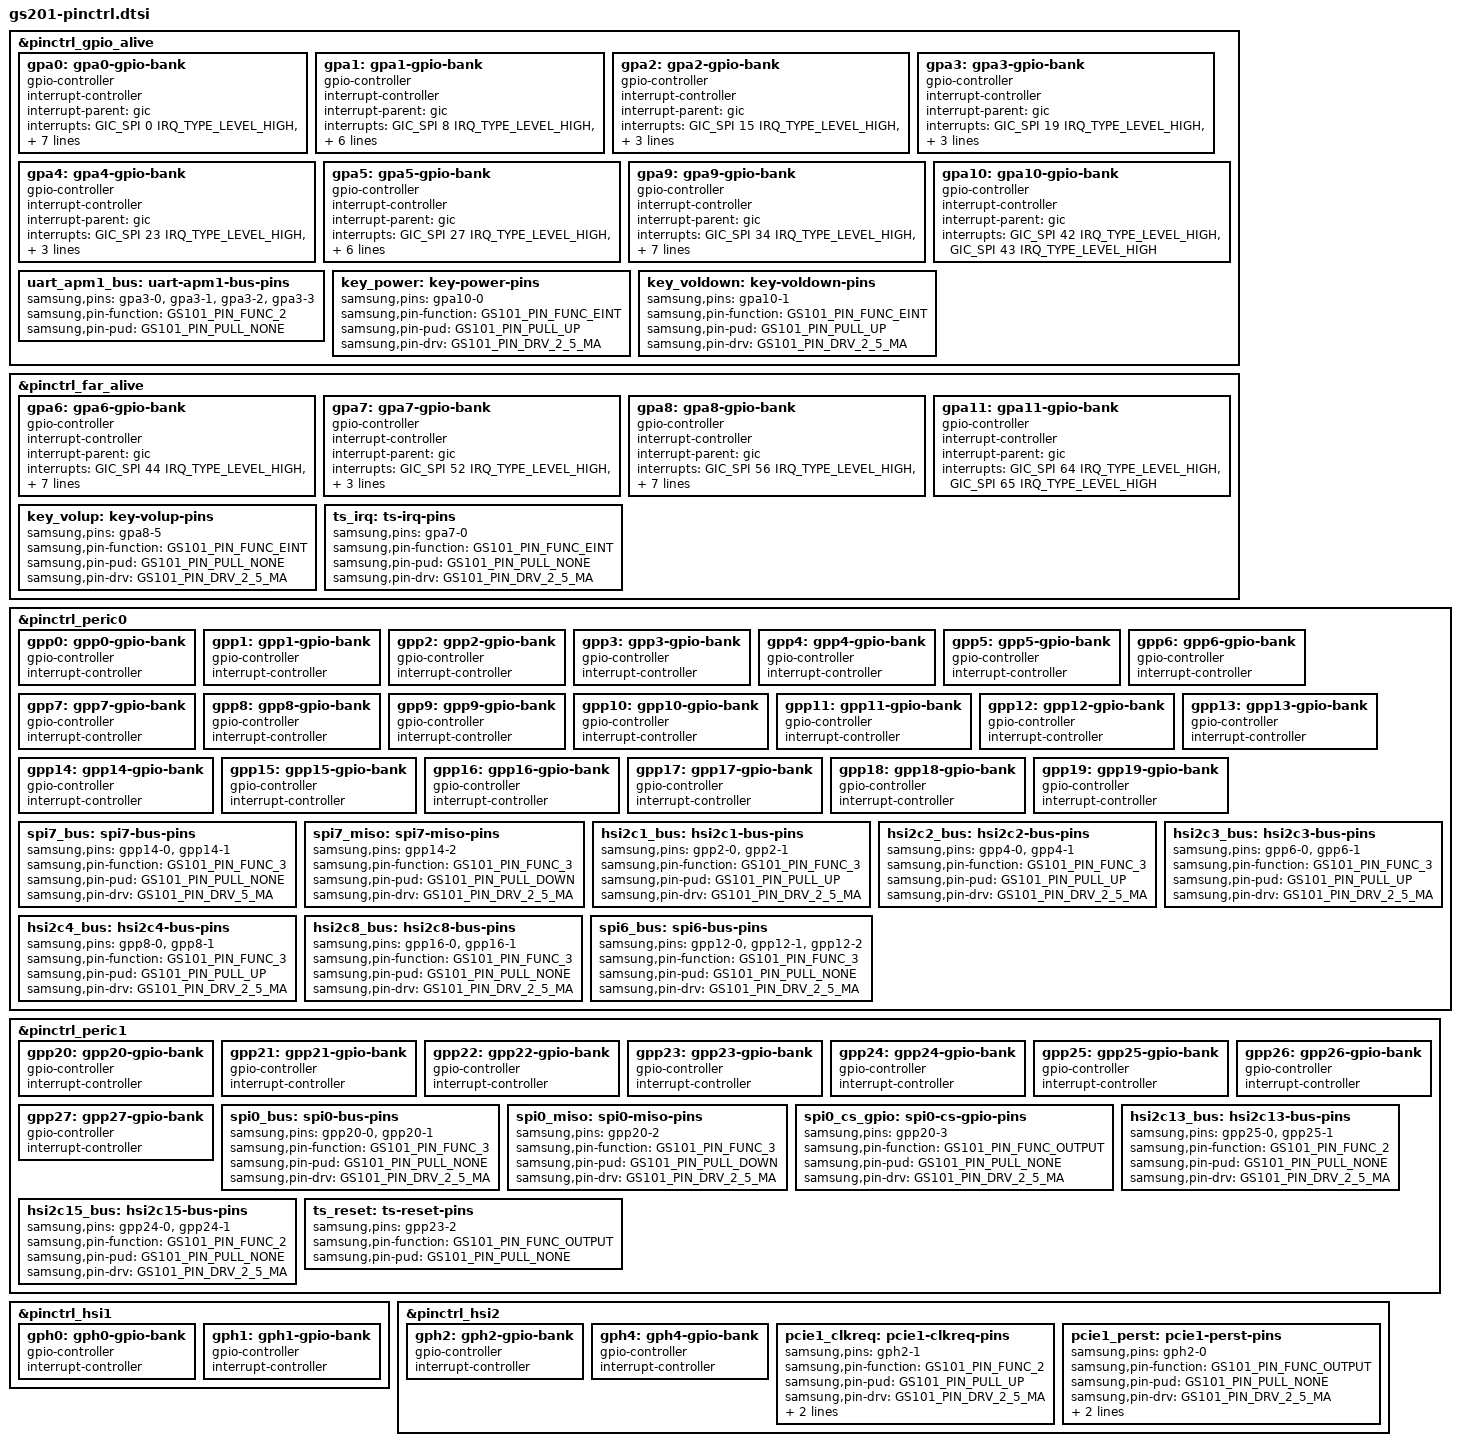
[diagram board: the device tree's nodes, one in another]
// SPDX-License-Identifier: GPL-2.0-only
/*
 * Google GS201 (Tensor G2) SoC pin-mux and pin-config device tree source
 *
 * Bank layout and wake-up interrupt numbers from Google's GPL gs201 device
 * tree. Note that the ALIVE wake-up interrupts skip EINT19, so from EINT20
 * on the GIC number is the EINT number minus one.
 */

#include "gs101-pinctrl.h"

&pinctrl_gpio_alive {
	gpa0: gpa0-gpio-bank {
		gpio-controller;
		#gpio-cells = <2>;
		interrupt-controller;
		#interrupt-cells = <2>;
		interrupt-parent = <&gic>;
		interrupts = <GIC_SPI 0 IRQ_TYPE_LEVEL_HIGH>,
			     <GIC_SPI 1 IRQ_TYPE_LEVEL_HIGH>,
			     <GIC_SPI 2 IRQ_TYPE_LEVEL_HIGH>,
			     <GIC_SPI 3 IRQ_TYPE_LEVEL_HIGH>,
			     <GIC_SPI 4 IRQ_TYPE_LEVEL_HIGH>,
			     <GIC_SPI 5 IRQ_TYPE_LEVEL_HIGH>,
			     <GIC_SPI 6 IRQ_TYPE_LEVEL_HIGH>,
			     <GIC_SPI 7 IRQ_TYPE_LEVEL_HIGH>;
	};

	gpa1: gpa1-gpio-bank {
		gpio-controller;
		#gpio-cells = <2>;
		interrupt-controller;
		#interrupt-cells = <2>;
		interrupt-parent = <&gic>;
		interrupts = <GIC_SPI 8 IRQ_TYPE_LEVEL_HIGH>,
			     <GIC_SPI 9 IRQ_TYPE_LEVEL_HIGH>,
			     <GIC_SPI 10 IRQ_TYPE_LEVEL_HIGH>,
			     <GIC_SPI 11 IRQ_TYPE_LEVEL_HIGH>,
			     <GIC_SPI 12 IRQ_TYPE_LEVEL_HIGH>,
			     <GIC_SPI 13 IRQ_TYPE_LEVEL_HIGH>,
			     <GIC_SPI 14 IRQ_TYPE_LEVEL_HIGH>;
	};

	gpa2: gpa2-gpio-bank {
		gpio-controller;
		#gpio-cells = <2>;
		interrupt-controller;
		#interrupt-cells = <2>;
		interrupt-parent = <&gic>;
		interrupts = <GIC_SPI 15 IRQ_TYPE_LEVEL_HIGH>,
			     <GIC_SPI 16 IRQ_TYPE_LEVEL_HIGH>,
			     <GIC_SPI 17 IRQ_TYPE_LEVEL_HIGH>,
			     <GIC_SPI 18 IRQ_TYPE_LEVEL_HIGH>;
	};

	gpa3: gpa3-gpio-bank {
		gpio-controller;
		#gpio-cells = <2>;
		interrupt-controller;
		#interrupt-cells = <2>;
		interrupt-parent = <&gic>;
		interrupts = <GIC_SPI 19 IRQ_TYPE_LEVEL_HIGH>,
			     <GIC_SPI 20 IRQ_TYPE_LEVEL_HIGH>,
			     <GIC_SPI 21 IRQ_TYPE_LEVEL_HIGH>,
			     <GIC_SPI 22 IRQ_TYPE_LEVEL_HIGH>;
	};

	gpa4: gpa4-gpio-bank {
		gpio-controller;
		#gpio-cells = <2>;
		interrupt-controller;
		#interrupt-cells = <2>;
		interrupt-parent = <&gic>;
		interrupts = <GIC_SPI 23 IRQ_TYPE_LEVEL_HIGH>,
			     <GIC_SPI 24 IRQ_TYPE_LEVEL_HIGH>,
			     <GIC_SPI 25 IRQ_TYPE_LEVEL_HIGH>,
			     <GIC_SPI 26 IRQ_TYPE_LEVEL_HIGH>;
	};

	gpa5: gpa5-gpio-bank {
		gpio-controller;
		#gpio-cells = <2>;
		interrupt-controller;
		#interrupt-cells = <2>;
		interrupt-parent = <&gic>;
		interrupts = <GIC_SPI 27 IRQ_TYPE_LEVEL_HIGH>,
			     <GIC_SPI 28 IRQ_TYPE_LEVEL_HIGH>,
			     <GIC_SPI 29 IRQ_TYPE_LEVEL_HIGH>,
			     <GIC_SPI 30 IRQ_TYPE_LEVEL_HIGH>,
			     <GIC_SPI 31 IRQ_TYPE_LEVEL_HIGH>,
			     <GIC_SPI 32 IRQ_TYPE_LEVEL_HIGH>,
			     <GIC_SPI 33 IRQ_TYPE_LEVEL_HIGH>;
	};

	gpa9: gpa9-gpio-bank {
		gpio-controller;
		#gpio-cells = <2>;
		interrupt-controller;
		#interrupt-cells = <2>;
		interrupt-parent = <&gic>;
		interrupts = <GIC_SPI 34 IRQ_TYPE_LEVEL_HIGH>,
			     <GIC_SPI 35 IRQ_TYPE_LEVEL_HIGH>,
			     <GIC_SPI 36 IRQ_TYPE_LEVEL_HIGH>,
			     <GIC_SPI 37 IRQ_TYPE_LEVEL_HIGH>,
			     <GIC_SPI 38 IRQ_TYPE_LEVEL_HIGH>,
			     <GIC_SPI 39 IRQ_TYPE_LEVEL_HIGH>,
			     <GIC_SPI 40 IRQ_TYPE_LEVEL_HIGH>,
			     <GIC_SPI 41 IRQ_TYPE_LEVEL_HIGH>;
	};

	gpa10: gpa10-gpio-bank {
		gpio-controller;
		#gpio-cells = <2>;
		interrupt-controller;
		#interrupt-cells = <2>;
		interrupt-parent = <&gic>;
		interrupts = <GIC_SPI 42 IRQ_TYPE_LEVEL_HIGH>,
			     <GIC_SPI 43 IRQ_TYPE_LEVEL_HIGH>;
	};

	/* APM USI1 UART: RXD, TXD, RTS_N, CTS_N */
	uart_apm1_bus: uart-apm1-bus-pins {
		samsung,pins = "gpa3-0", "gpa3-1", "gpa3-2", "gpa3-3";
		samsung,pin-function = <GS101_PIN_FUNC_2>;
		samsung,pin-pud = <GS101_PIN_PULL_NONE>;
	};

	key_power: key-power-pins {
		samsung,pins = "gpa10-0";
		samsung,pin-function = <GS101_PIN_FUNC_EINT>;
		samsung,pin-pud = <GS101_PIN_PULL_UP>;
		samsung,pin-drv = <GS101_PIN_DRV_2_5_MA>;
	};

	key_voldown: key-voldown-pins {
		samsung,pins = "gpa10-1";
		samsung,pin-function = <GS101_PIN_FUNC_EINT>;
		samsung,pin-pud = <GS101_PIN_PULL_UP>;
		samsung,pin-drv = <GS101_PIN_DRV_2_5_MA>;
	};
};

&pinctrl_far_alive {
	gpa6: gpa6-gpio-bank {
		gpio-controller;
		#gpio-cells = <2>;
		interrupt-controller;
		#interrupt-cells = <2>;
		interrupt-parent = <&gic>;
		interrupts = <GIC_SPI 44 IRQ_TYPE_LEVEL_HIGH>,
			     <GIC_SPI 45 IRQ_TYPE_LEVEL_HIGH>,
			     <GIC_SPI 46 IRQ_TYPE_LEVEL_HIGH>,
			     <GIC_SPI 47 IRQ_TYPE_LEVEL_HIGH>,
			     <GIC_SPI 48 IRQ_TYPE_LEVEL_HIGH>,
			     <GIC_SPI 49 IRQ_TYPE_LEVEL_HIGH>,
			     <GIC_SPI 50 IRQ_TYPE_LEVEL_HIGH>,
			     <GIC_SPI 51 IRQ_TYPE_LEVEL_HIGH>;
	};

	gpa7: gpa7-gpio-bank {
		gpio-controller;
		#gpio-cells = <2>;
		interrupt-controller;
		#interrupt-cells = <2>;
		interrupt-parent = <&gic>;
		interrupts = <GIC_SPI 52 IRQ_TYPE_LEVEL_HIGH>,
			     <GIC_SPI 53 IRQ_TYPE_LEVEL_HIGH>,
			     <GIC_SPI 54 IRQ_TYPE_LEVEL_HIGH>,
			     <GIC_SPI 55 IRQ_TYPE_LEVEL_HIGH>;
	};

	gpa8: gpa8-gpio-bank {
		gpio-controller;
		#gpio-cells = <2>;
		interrupt-controller;
		#interrupt-cells = <2>;
		interrupt-parent = <&gic>;
		interrupts = <GIC_SPI 56 IRQ_TYPE_LEVEL_HIGH>,
			     <GIC_SPI 57 IRQ_TYPE_LEVEL_HIGH>,
			     <GIC_SPI 58 IRQ_TYPE_LEVEL_HIGH>,
			     <GIC_SPI 59 IRQ_TYPE_LEVEL_HIGH>,
			     <GIC_SPI 60 IRQ_TYPE_LEVEL_HIGH>,
			     <GIC_SPI 61 IRQ_TYPE_LEVEL_HIGH>,
			     <GIC_SPI 62 IRQ_TYPE_LEVEL_HIGH>,
			     <GIC_SPI 63 IRQ_TYPE_LEVEL_HIGH>;
	};

	gpa11: gpa11-gpio-bank {
		gpio-controller;
		#gpio-cells = <2>;
		interrupt-controller;
		#interrupt-cells = <2>;
		interrupt-parent = <&gic>;
		interrupts = <GIC_SPI 64 IRQ_TYPE_LEVEL_HIGH>,
			     <GIC_SPI 65 IRQ_TYPE_LEVEL_HIGH>;
	};

	key_volup: key-volup-pins {
		samsung,pins = "gpa8-5";
		samsung,pin-function = <GS101_PIN_FUNC_EINT>;
		samsung,pin-pud = <GS101_PIN_PULL_NONE>;
		samsung,pin-drv = <GS101_PIN_DRV_2_5_MA>;
	};

	ts_irq: ts-irq-pins {
		samsung,pins = "gpa7-0";
		samsung,pin-function = <GS101_PIN_FUNC_EINT>;
		samsung,pin-pud = <GS101_PIN_PULL_NONE>;
		samsung,pin-drv = <GS101_PIN_DRV_2_5_MA>;
	};
};

&pinctrl_peric0 {
	gpp0: gpp0-gpio-bank {
		gpio-controller;
		#gpio-cells = <2>;
		interrupt-controller;
		#interrupt-cells = <2>;
	};

	gpp1: gpp1-gpio-bank {
		gpio-controller;
		#gpio-cells = <2>;
		interrupt-controller;
		#interrupt-cells = <2>;
	};

	gpp2: gpp2-gpio-bank {
		gpio-controller;
		#gpio-cells = <2>;
		interrupt-controller;
		#interrupt-cells = <2>;
	};

	gpp3: gpp3-gpio-bank {
		gpio-controller;
		#gpio-cells = <2>;
		interrupt-controller;
		#interrupt-cells = <2>;
	};

	gpp4: gpp4-gpio-bank {
		gpio-controller;
		#gpio-cells = <2>;
		interrupt-controller;
		#interrupt-cells = <2>;
	};

	gpp5: gpp5-gpio-bank {
		gpio-controller;
		#gpio-cells = <2>;
		interrupt-controller;
		#interrupt-cells = <2>;
	};

	gpp6: gpp6-gpio-bank {
		gpio-controller;
		#gpio-cells = <2>;
		interrupt-controller;
		#interrupt-cells = <2>;
	};

	gpp7: gpp7-gpio-bank {
		gpio-controller;
		#gpio-cells = <2>;
		interrupt-controller;
		#interrupt-cells = <2>;
	};

	gpp8: gpp8-gpio-bank {
		gpio-controller;
		#gpio-cells = <2>;
		interrupt-controller;
		#interrupt-cells = <2>;
	};

	gpp9: gpp9-gpio-bank {
		gpio-controller;
		#gpio-cells = <2>;
		interrupt-controller;
		#interrupt-cells = <2>;
	};

	gpp10: gpp10-gpio-bank {
		gpio-controller;
		#gpio-cells = <2>;
		interrupt-controller;
		#interrupt-cells = <2>;
	};

	gpp11: gpp11-gpio-bank {
		gpio-controller;
		#gpio-cells = <2>;
		interrupt-controller;
		#interrupt-cells = <2>;
	};

	gpp12: gpp12-gpio-bank {
		gpio-controller;
		#gpio-cells = <2>;
		interrupt-controller;
		#interrupt-cells = <2>;
	};

	gpp13: gpp13-gpio-bank {
		gpio-controller;
		#gpio-cells = <2>;
		interrupt-controller;
		#interrupt-cells = <2>;
	};

	gpp14: gpp14-gpio-bank {
		gpio-controller;
		#gpio-cells = <2>;
		interrupt-controller;
		#interrupt-cells = <2>;
	};

	gpp15: gpp15-gpio-bank {
		gpio-controller;
		#gpio-cells = <2>;
		interrupt-controller;
		#interrupt-cells = <2>;
	};

	gpp16: gpp16-gpio-bank {
		gpio-controller;
		#gpio-cells = <2>;
		interrupt-controller;
		#interrupt-cells = <2>;
	};

	gpp17: gpp17-gpio-bank {
		gpio-controller;
		#gpio-cells = <2>;
		interrupt-controller;
		#interrupt-cells = <2>;
	};

	gpp18: gpp18-gpio-bank {
		gpio-controller;
		#gpio-cells = <2>;
		interrupt-controller;
		#interrupt-cells = <2>;
	};

	gpp19: gpp19-gpio-bank {
		gpio-controller;
		#gpio-cells = <2>;
		interrupt-controller;
		#interrupt-cells = <2>;
	};

	spi7_bus: spi7-bus-pins {
		samsung,pins = "gpp14-0", "gpp14-1";
		samsung,pin-function = <GS101_PIN_FUNC_3>;
		samsung,pin-pud = <GS101_PIN_PULL_NONE>;
		samsung,pin-drv = <GS101_PIN_DRV_5_MA>;
	};

	spi7_miso: spi7-miso-pins {
		samsung,pins = "gpp14-2";
		samsung,pin-function = <GS101_PIN_FUNC_3>;
		samsung,pin-pud = <GS101_PIN_PULL_DOWN>;
		samsung,pin-drv = <GS101_PIN_DRV_2_5_MA>;
	};

	/* Camera I2C (main module); stock pulls the lines up while it transfers */
	hsi2c1_bus: hsi2c1-bus-pins {
		samsung,pins = "gpp2-0", "gpp2-1";
		samsung,pin-function = <GS101_PIN_FUNC_3>;
		samsung,pin-pud = <GS101_PIN_PULL_UP>;
		samsung,pin-drv = <GS101_PIN_DRV_2_5_MA>;
	};

	/* Camera I2C (front module); stock pulls the lines up while it transfers */
	hsi2c2_bus: hsi2c2-bus-pins {
		samsung,pins = "gpp4-0", "gpp4-1";
		samsung,pin-function = <GS101_PIN_FUNC_3>;
		samsung,pin-pud = <GS101_PIN_PULL_UP>;
		samsung,pin-drv = <GS101_PIN_DRV_2_5_MA>;
	};

	/* Camera I2C (ultrawide module); stock pulls the lines up while it transfers */
	hsi2c3_bus: hsi2c3-bus-pins {
		samsung,pins = "gpp6-0", "gpp6-1";
		samsung,pin-function = <GS101_PIN_FUNC_3>;
		samsung,pin-pud = <GS101_PIN_PULL_UP>;
		samsung,pin-drv = <GS101_PIN_DRV_2_5_MA>;
	};

	/* Camera I2C (telephoto module); stock pulls the lines up while it transfers */
	hsi2c4_bus: hsi2c4-bus-pins {
		samsung,pins = "gpp8-0", "gpp8-1";
		samsung,pin-function = <GS101_PIN_FUNC_3>;
		samsung,pin-pud = <GS101_PIN_PULL_UP>;
		samsung,pin-drv = <GS101_PIN_DRV_2_5_MA>;
	};

	hsi2c8_bus: hsi2c8-bus-pins {
		samsung,pins = "gpp16-0", "gpp16-1";
		samsung,pin-function = <GS101_PIN_FUNC_3>;
		samsung,pin-pud = <GS101_PIN_PULL_NONE>;
		samsung,pin-drv = <GS101_PIN_DRV_2_5_MA>;
	};

	spi6_bus: spi6-bus-pins {
		samsung,pins = "gpp12-0", "gpp12-1", "gpp12-2";
		samsung,pin-function = <GS101_PIN_FUNC_3>;
		samsung,pin-pud = <GS101_PIN_PULL_NONE>;
		samsung,pin-drv = <GS101_PIN_DRV_2_5_MA>;
	};

};

&pinctrl_peric1 {
	gpp20: gpp20-gpio-bank {
		gpio-controller;
		#gpio-cells = <2>;
		interrupt-controller;
		#interrupt-cells = <2>;
	};

	gpp21: gpp21-gpio-bank {
		gpio-controller;
		#gpio-cells = <2>;
		interrupt-controller;
		#interrupt-cells = <2>;
	};

	gpp22: gpp22-gpio-bank {
		gpio-controller;
		#gpio-cells = <2>;
		interrupt-controller;
		#interrupt-cells = <2>;
	};

	gpp23: gpp23-gpio-bank {
		gpio-controller;
		#gpio-cells = <2>;
		interrupt-controller;
		#interrupt-cells = <2>;
	};

	gpp24: gpp24-gpio-bank {
		gpio-controller;
		#gpio-cells = <2>;
		interrupt-controller;
		#interrupt-cells = <2>;
	};

	gpp25: gpp25-gpio-bank {
		gpio-controller;
		#gpio-cells = <2>;
		interrupt-controller;
		#interrupt-cells = <2>;
	};

	gpp26: gpp26-gpio-bank {
		gpio-controller;
		#gpio-cells = <2>;
		interrupt-controller;
		#interrupt-cells = <2>;
	};

	gpp27: gpp27-gpio-bank {
		gpio-controller;
		#gpio-cells = <2>;
		interrupt-controller;
		#interrupt-cells = <2>;
	};

	spi0_bus: spi0-bus-pins {
		samsung,pins = "gpp20-0", "gpp20-1";
		samsung,pin-function = <GS101_PIN_FUNC_3>;
		samsung,pin-pud = <GS101_PIN_PULL_NONE>;
		samsung,pin-drv = <GS101_PIN_DRV_2_5_MA>;
	};

	spi0_miso: spi0-miso-pins {
		samsung,pins = "gpp20-2";
		samsung,pin-function = <GS101_PIN_FUNC_3>;
		samsung,pin-pud = <GS101_PIN_PULL_DOWN>;
		samsung,pin-drv = <GS101_PIN_DRV_2_5_MA>;
	};

	spi0_cs_gpio: spi0-cs-gpio-pins {
		samsung,pins = "gpp20-3";
		samsung,pin-function = <GS101_PIN_FUNC_OUTPUT>;
		samsung,pin-pud = <GS101_PIN_PULL_NONE>;
		samsung,pin-drv = <GS101_PIN_DRV_2_5_MA>;
	};

	hsi2c13_bus: hsi2c13-bus-pins {
		samsung,pins = "gpp25-0", "gpp25-1";
		samsung,pin-function = <GS101_PIN_FUNC_2>;
		samsung,pin-pud = <GS101_PIN_PULL_NONE>;
		samsung,pin-drv = <GS101_PIN_DRV_2_5_MA>;
	};

	hsi2c15_bus: hsi2c15-bus-pins {
		samsung,pins = "gpp24-0", "gpp24-1";
		samsung,pin-function = <GS101_PIN_FUNC_2>;
		samsung,pin-pud = <GS101_PIN_PULL_NONE>;
		samsung,pin-drv = <GS101_PIN_DRV_2_5_MA>;
	};

	ts_reset: ts-reset-pins {
		samsung,pins = "gpp23-2";
		samsung,pin-function = <GS101_PIN_FUNC_OUTPUT>;
		samsung,pin-pud = <GS101_PIN_PULL_NONE>;
	};
};

&pinctrl_hsi1 {
	gph0: gph0-gpio-bank {
		gpio-controller;
		#gpio-cells = <2>;
		interrupt-controller;
		#interrupt-cells = <2>;
	};

	gph1: gph1-gpio-bank {
		gpio-controller;
		#gpio-cells = <2>;
		interrupt-controller;
		#interrupt-cells = <2>;
	};

};

&pinctrl_hsi2 {
	gph2: gph2-gpio-bank {
		gpio-controller;
		#gpio-cells = <2>;
		interrupt-controller;
		#interrupt-cells = <2>;
	};

	gph4: gph4-gpio-bank {
		gpio-controller;
		#gpio-cells = <2>;
		interrupt-controller;
		#interrupt-cells = <2>;
	};

	pcie1_clkreq: pcie1-clkreq-pins {
		samsung,pins = "gph2-1";
		samsung,pin-function = <GS101_PIN_FUNC_2>;
		samsung,pin-pud = <GS101_PIN_PULL_UP>;
		samsung,pin-drv = <GS101_PIN_DRV_2_5_MA>;
		samsung,pin-con-pdn = <GS101_PIN_PDN_PREV>;
		samsung,pin-pud-pdn = <GS101_PIN_PULL_UP>;
	};

	pcie1_perst: pcie1-perst-pins {
		samsung,pins = "gph2-0";
		samsung,pin-function = <GS101_PIN_FUNC_OUTPUT>;
		samsung,pin-pud = <GS101_PIN_PULL_NONE>;
		samsung,pin-drv = <GS101_PIN_DRV_2_5_MA>;
		samsung,pin-con-pdn = <GS101_PIN_PDN_PREV>;
		samsung,pin-pud-pdn = <GS101_PIN_PULL_NONE>;
	};
};
